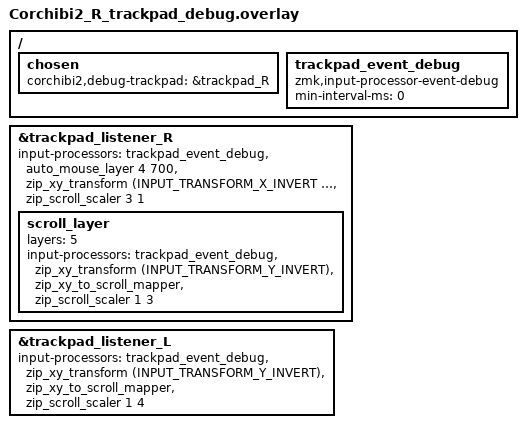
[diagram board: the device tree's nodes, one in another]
#include "../Corchibi2/Corchibi2_R.overlay"

/ {
    chosen {
        corchibi2,debug-trackpad = &trackpad_R;
    };

    trackpad_event_debug: trackpad_event_debug {
        compatible = "zmk,input-processor-event-debug";
        #input-processor-cells = <0>;
        min-interval-ms = <0>;
    };
};

&trackpad_listener_R {
    input-processors =
        <&trackpad_event_debug>,
        <&auto_mouse_layer 4 700>,
        <&zip_xy_transform (INPUT_TRANSFORM_X_INVERT | INPUT_TRANSFORM_Y_INVERT)>,
        <&zip_scroll_scaler 3 1>;

    scroll_layer {
        layers = <5>;
        input-processors =
            <&trackpad_event_debug>,
            <&zip_xy_transform (INPUT_TRANSFORM_Y_INVERT)>,
            <&zip_xy_to_scroll_mapper>,
            <&zip_scroll_scaler 1 3>;
    };
};

&trackpad_listener_L {
    input-processors =
        <&trackpad_event_debug>,
        <&zip_xy_transform (INPUT_TRANSFORM_Y_INVERT)>,
        <&zip_xy_to_scroll_mapper>,
        <&zip_scroll_scaler 1 4>;
};
